# RL6955_IP_SVD register map
Vendor: Realtek
Registers are 32-bit, read-write, reset 0x0 unless marked. A register's access mark holds for its fields unless they carry their own. Offsets are from the block's base; [hi:lo] are bit positions; lines under a group give offsets from that group; {n}, {i} and the like mark numbered series; 'fields as' and 'values as' point back to an identical list.

## RXI300_REG
Base 0x41892000
Same registers: RXI300_S_ELR_REG 0x41892100, RXI300_S_DIR_REG 0x41892200, RXI300_NS_GPR_REG 0x41893000, RXI300_NS_ELR_REG 0x41893100, RXI300_NS_DIR_REG 0x41893200, RXI300_NS_TMO_REG 0x41893300, PPC_S 0x51892000, MPC1_S 0x51892400, MPC2_S 0x51892500, MPC3_S 0x51892600
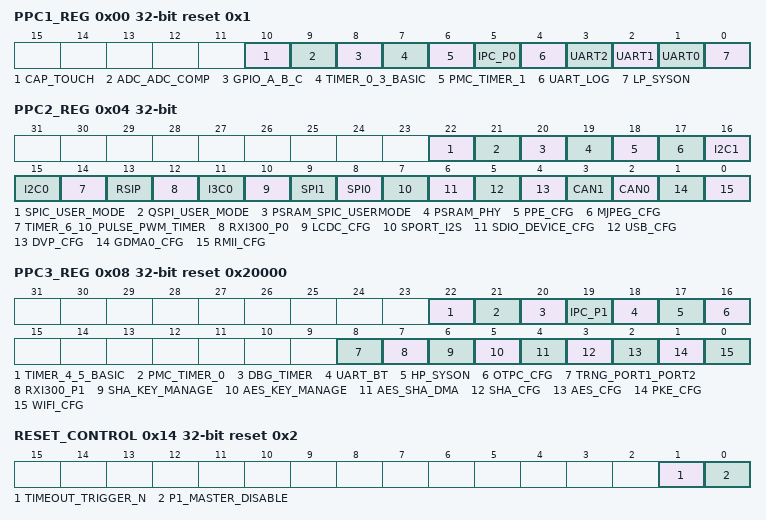
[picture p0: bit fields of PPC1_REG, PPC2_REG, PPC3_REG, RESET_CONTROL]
0x00 PPC1_REG reset 0x1 — PPC1 configure register
  [10] CAP_TOUCH — 1: Non-secure attribution 0: Secure attribution
  [9] ADC_ADC_COMP — 1: Non-secure attribution 0: Secure attribution
  [8] GPIO_A_B_C — 1: Non-secure attribution 0: Secure attribution
  [7] TIMER_0_3_BASIC — 1: Non-secure attribution 0: Secure attribution
  [6] PMC_TIMER_1 — 1: Non-secure attribution 0: Secure attribution
  [5] IPC_P0 — 1: Non-secure attribution 0: Secure attribution
  [4] UART_LOG — 1: Non-secure attribution 0: Secure attribution
  [3] UART2 — 1: Non-secure attribution 0: Secure attribution
  [2] UART1 — 1: Non-secure attribution 0: Secure attribution
  [1] UART0 — 1: Non-secure attribution 0: Secure attribution
  [0] LP_SYSON — 1: Non-secure attribution 0: Secure attribution
0x04 PPC2_REG — PPC2 configure register
  [22] SPIC_USER_MODE — 1: Non-secure attribution 0: Secure attribution
  [21] QSPI_USER_MODE — 1: Non-secure attribution 0: Secure attribution
  [20] PSRAM_SPIC_USERMODE — 1: Non-secure attribution 0: Secure attribution
  [19] PSRAM_PHY — 1: Non-secure attribution 0: Secure attribution
  [18] PPE_CFG — 1: Non-secure attribution 0: Secure attribution
  [17] MJPEG_CFG — 1: Non-secure attribution 0: Secure attribution
  [16] I2C1 — 1: Non-secure attribution 0: Secure attribution
  [15] I2C0 — 1: Non-secure attribution 0: Secure attribution
  [14] TIMER_6_10_PULSE_PWM_TIMER — 1: Non-secure attribution 0: Secure attribution
  [13] RSIP — 1: Non-secure attribution 0: Secure attribution
  [12] RXI300_P0 — 1: Non-secure attribution 0: Secure attribution
  [11] I3C0 — 1: Non-secure attribution 0: Secure attribution
  [10] LCDC_CFG — 1: Non-secure attribution 0: Secure attribution
  [9] SPI1 — 1: Non-secure attribution 0: Secure attribution
  [8] SPI0 — 1: Non-secure attribution 0: Secure attribution
  [7] SPORT_I2S — 1: Non-secure attribution 0: Secure attribution
  [6] SDIO_DEVICE_CFG — 1: Non-secure attribution 0: Secure attribution
  [5] USB_CFG — 1: Non-secure attribution 0: Secure attribution
  [4] DVP_CFG — 1: Non-secure attribution 0: Secure attribution
  [3] CAN1 — 1: Non-secure attribution 0: Secure attribution
  [2] CAN0 — 1: Non-secure attribution 0: Secure attribution
  [1] GDMA0_CFG — 1: Non-secure attribution 0: Secure attribution
  [0] RMII_CFG — 1: Non-secure attribution 0: Secure attribution
0x08 PPC3_REG reset 0x20000 — PPC3 configure register
  [22] TIMER_4_5_BASIC — 1: Non-secure attribution 2: Secure attribution
  [21] PMC_TIMER_0 — 1: Non-secure attribution 1: Secure attribution
  [20] DBG_TIMER — 1: Non-secure attribution 0: Secure attribution
  [19] IPC_P1 — 1: Non-secure attribution 0: Secure attribution
  [18] UART_BT — 1: Non-secure attribution 0: Secure attribution
  [17] HP_SYSON — 1: Non-secure attribution 0: Secure attribution
  [16] OTPC_CFG — 1: Non-secure attribution 0: Secure attribution
  [8] TRNG_PORT1_PORT2 — 1: Non-secure attribution 0: Secure attribution
  [7] RXI300_P1 — 1: Non-secure attribution 0: Secure attribution
  [6] SHA_KEY_MANAGE — 1: Non-secure attribution 0: Secure attribution
  [5] AES_KEY_MANAGE — 1: Non-secure attribution 0: Secure attribution
  [4] AES_SHA_DMA — 1: Non-secure attribution 0: Secure attribution
  [3] SHA_CFG — 1: Non-secure attribution 0: Secure attribution
  [2] AES_CFG — 1: Non-secure attribution 0: Secure attribution
  [1] PKE_CFG — 1: Non-secure attribution 0: Secure attribution
  [0] WIFI_CFG — 1: Non-secure attribution 0: Secure attribution
0x0C PPC_LOCK
  [0] LOCK — PPC lock register. When writing 1'b1 to this bit, PPC will be locked. Note: It can not be written to 1'b0 again until system reset to prevent modification. When PPC is locked, you can not program PPC registers unless system reset.
0x10 DISCONNECT_PLFM1 — Disconnect platform register1
  [0] DISCONNECT_PLFM1 — Platform1-to-platform0 peripheral path are 0x0: connect 0x1: disconnect When writing 1'b1 to this bit, the register willl be locked. NOTE: It can not be written to 1'b0 again until system reset to prevent modification.When this regitster is locked, you can not program this register unless system reset.
0x14 RESET_CONTROL reset 0x2 — Reset flow control register
  [1] TIMEOUT_TRIGGER_N — Trigger all timeout monitors in platform0 to block transaction from platform1. 0x0: trigger timeout 0x1: idle NOTE: The register is not a write-1-clear register. User should set this register to 0x1(idle) after timeout is triggered.
  [0] P1_MASTER_DISABLE — Master enable signal. All master agent of platform1-to-platform are 0x0: enable 0x1: disable
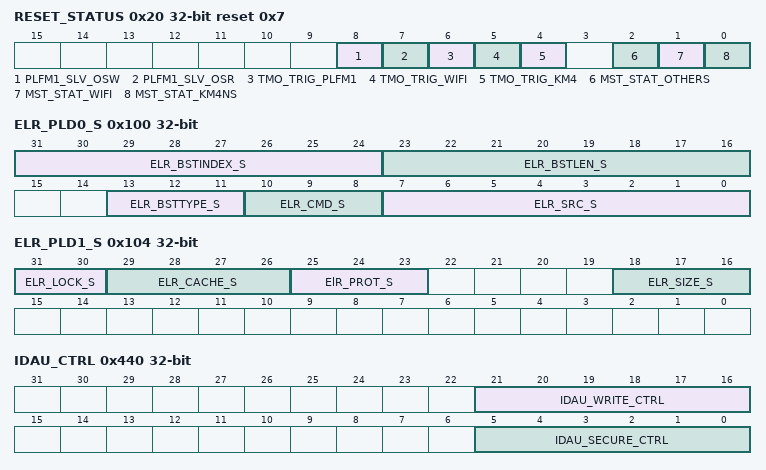
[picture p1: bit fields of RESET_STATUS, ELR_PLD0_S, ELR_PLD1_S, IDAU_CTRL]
0x20 RESET_STATUS ro reset 0x7 — Reset flow status register
  [8] PLFM1_SLV_OSW — Write transaction number of KM4TZ which remains in platform1 slaves.The platform1 slaves are 0x0: idle 0x1: has at least one write OST
  [7] PLFM1_SLV_OSR — Read transaction number of KM4TZ which remains in platform1 slaves.The platform1 slaves are 0x0: idle 0x1: has at least one read OST
  [6] TMO_TRIG_PLFM1 — Status of AES_SHA/SIC/OTPC/WIFI timeout monitor.The timeout is 0x0: disable 0x1: enable
  [5] TMO_TRIG_WIFI — Status of WIFI timeout monitor.The timeout is 0x0: disable 0x0: enable
  [4] TMO_TRIG_KM4 — Status of CPU domain timeout monitor.The timeout is 0x0: disable 0x1: enable
  [2] MST_STAT_OTHERS — Status of AES_SHA/SIC/OTPC/WIFI master agent. The master is 0x0: idle 0x1: active
  [1] MST_STAT_WIFI — Status of WIFI master agent. The master is 0x0: idle 0x1: active
  [0] MST_STAT_KM4NS — Status of KM4NS master agent. The master is 0x0: idle 0x1: active
0x100 ELR_PLD0_S ro — Error log payload register0
  [31:24] ELR_BSTINDEX_S — Burst index of the error request.
  [23:16] ELR_BSTLEN_S — Burst Length of the error request.
  [13:11] ELR_BSTTYPE_S — BurstSeq of the error request.
  [10:8] ELR_CMD_S — CMD of the error request. 0x1: Write command 0x2: Read command
  [7:0] ELR_SRC_S — Error source of the error request. 0x10: secure default slave of P0S0 0x11: secure default slave of P0S1-12~P0S1-16 0x12: secure default slave of P0S1-5~P0S1-7 0x13: secure default slave of P0S1-1~P0S1-4, P0S1-8~P0S1-11 0x14: secure default slave of P0S1-0 0x15: secure default slave of P0S1-22 0x16: secure default slave of P0S1-19~P0S1-21, P0S2 0x17: secure default slave of P0S1-17, P0S1-18 0x20: secure default slave of P2S0 0x21: secure default slave of P3S0 0x22: secure default slave of P4S0
0x104 ELR_PLD1_S ro — Error log payload register1
  [31:30] ELR_LOCK_S — AxLock of the error request.
  [29:26] ELR_CACHE_S — AxCache of the error request.
  [25:23] ElR_PROT_S — AxProt of the error request.
  [18:16] ELR_SIZE_S — Size of the error request.
0x108 ELR_ID_S ro — Error log ID information register
  [31:0] ELR_ID_S — Tagid of the error request. 8'b00000???: M0 access error 8'b000100??: M1 access error 8'b0100????: M2 access error 8'b000101??: M3 access error 8'b0101000?: M4 access error 8'b0001100?: M5 access error 8'b01100???: M6 access error 8'b001?????: M7 access error 8'b1101????: M8 access error 8'b11100???: M9 access error 8'b1111000?: M10 access error 8'b101?????: M11 access error
0x10C ELR_ADR0_S ro — Error log addrress register0
  [31:0] ELR_ADR0_S — Address[31:0] of the error request.
0x110 ELR_ADR1_S ro — Error log addrress register1
  [63:32] ELR_ADR1_S — Address[63:32] of the error request.
0x130 ELR_CODE_S ro — Error code register
  [7:0] ELR_CODE_S — The error code of error request, if it's 0, indicates that there is no error request. 8'h00: No error 8'h02: Secure fault error
0x13C ELR_INTR_CLR_S wo — Error log clear register
  [0] ELR_INTR_CLR_S — Error log interrupt clear. Writing 1'b1 to the register will trigger a 1-cycle pulse interrupt clear. It has to write 1'b1 to this register every time when the error exception occurs. Note that this register is write-only, the return value of reading this register is meaningless.
0x200 NAME ro reset 0x52300 — RXI300 design name register
  [31:0] NAME — The design name of RXI-300.
0x204 VER ro reset 0x300 — RXI300 design version register
  [31:0] VER — The design version of RXI-300.
0x208 RVE ro reset 0x3 — RXI300 design reversion register
  [31:0] REV — The design reversion of RXI-300.
0x20C INST ro — RXI300 design instance number register
  [31:0] INST — The design instance number of RXI-300.
0x210 IMPL_Y ro reset 0x2025 — RXI300 implementation year register
  [31:0] IMPL_Y — The implementatin year of RXI-300. Reset value depends on implementation date.
0x214 IMPL_D ro reset 0x3211627 — RXI300 implementation date register
  [31:0] IMPL_D — The implementatin date of RXI-300. Reset value depends on implementation date.
0x218 DEV ro reset 0x5207433 — RXI300 developer register
  [31:0] DEV — The developer of RXI-300.
0x21C PRO_NUM ro reset 0x6955 — RXI300 project number register
  [31:0] PRO_NUM — The project number of RXI-300.
{0x400+8i} IDAU_BA{i} (i=0..5) — Base address register {i} in IDAU
  [27:12] IDAU_BA{i} — It's the base address of region {i} which can be set as non-secure. [27:12]: base address of region {i}
{0x404+8i} IDAU_LA{i} (i=0..5) — Top address register {i} in IDAU
  [27:12] IDAU_LA{i} — It's the top address of region {i} which can be set as non-secure. [27:12]: top address of region {i}
0x440 IDAU_CTRL — Enable control register in IDAU
  [21:16] IDAU_WRITE_CTRL — Region entry enable After setting WRITE_CTRL bits as 1, corresponding regions is set as write-forbidden.Note that if WRITE_CTRL bits are not enabled, the region remains secure even if ba*i/la*i is set. [16]: enable entry for ba0/la0 0: disable 1: enable [17]: enable entry for ba1/la1 0: disable 1: enable [18]: enable entry for ba2/la2 0: disable 1: enable [19]: enable entry for ba3/la3 0: disable 1: enable [20]: enable entry for ba4/la4 0: disable 1: enable [21]: enable entry for ba5/la5 0: disable 1: enable
  [5:0] IDAU_SECURE_CTRL — Region entry enable After setting SECURE_CTRL bits as 1, corresponding regions is set as non-secure.Note that if SECURE_CTRL bits are not enabled, the region remains secure even if ba*i/la*i is set. [0]: enable entry for ba0/la0 0: disable 1: enable [1]: enable entry for ba1/la1 0: disable 1: enable [2]: enable entry for ba2/la2 0: disable 1: enable [3]: enable entry for ba3/la3 0: disable 1: enable [4]: enable entry for ba4/la4 0: disable 1: enable [5]: enable entry for ba5/la5 0: disable 1: enable
0x444 IDAU_LOCK — Lock control register in IDAU
  [0] IDAU_LOCK — Lock write transfer for all registers in IDAU (including lock register itself) until system reset if it is ebabled. [0]: lock bit for all register in IDAU 0: disable lock 1: enable lock
{0x500+8i} IDAU1_BA{i} (i=0..5) — Base address register {i} in IDAU
  [27:12] IDAU1_BA{i} — It's the base address of region {i} which can be set as non-secure. [27:12]: base address of region {i}
{0x504+8i} IDAU1_LA{i} reset 0xF000000 (i=0..5) — Top address register {i} in IDAU
  [27:12] IDAU1_LA{i} — It's the top address of region {i} which can be set as non-secure. [27:12]: top address of region {i}
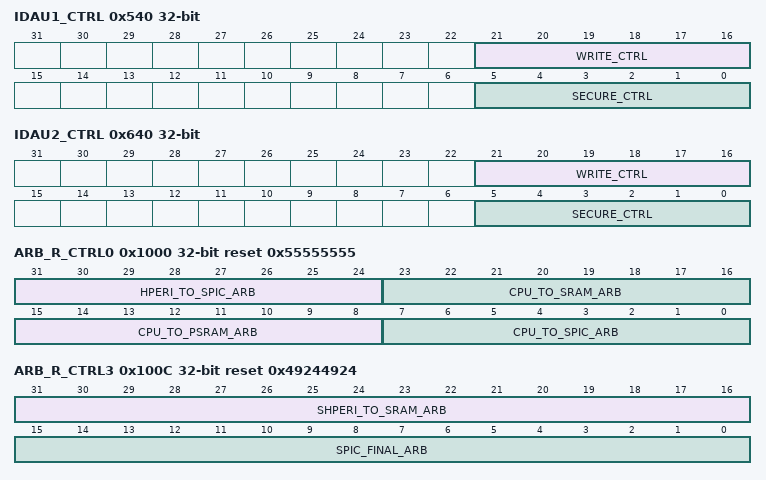
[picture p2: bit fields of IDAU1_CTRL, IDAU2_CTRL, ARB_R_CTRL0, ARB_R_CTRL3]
0x540 IDAU1_CTRL — Enable control register in IDAU
  [21:16] WRITE_CTRL — Region entry enable After setting WRITE_CTRL bits as 1, corresponding regions is set as write-forbidden.Note that if WRITE_CTRL bits are not enabled, the region remains secure even if ba*i/la*i is set. [16]: enable entry for ba0/la0 0: disable 1: enable [17]: enable entry for ba1/la1 0: disable 1: enable [18]: enable entry for ba2/la2 0: disable 1: enable [19]: enable entry for ba3/la3 0: disable 1: enable [20]: enable entry for ba4/la4 0: disable 1: enable [21]: enable entry for ba5/la5 0: disable 1: enable
  [5:0] SECURE_CTRL — Region entry enable After setting SECURE_CTRL bits as 1, corresponding regions is set as non-secure.Note that if SECURE_CTRL bits are not enabled, the region remains secure even if ba*i/la*i is set. [0]: enable entry for ba0/la0 0: disable 1: enable [1]: enable entry for ba1/la1 0: disable 1: enable [2]: enable entry for ba2/la2 0: disable 1: enable [3]: enable entry for ba3/la3 0: disable 1: enable [4]: enable entry for ba4/la4 0: disable 1: enable [5]: enable entry for ba5/la5 0: disable 1: enable
0x544 IDAU1_LOCK — Lock control register in IDAU
  fields as IDAU_LOCK
{0x600+8i} IDAU2_BA{i} (i=0..5) — Base address register {i} in IDAU
  [27:12] IDAU2_BA{i} — It's the base address of region {i} which can be set as non-secure. [27:12]: base address of region {i}
{0x604+8i} IDAU2_LA{i} reset 0xF000000 (i=0..5) — Top address register {i} in IDAU
  [27:12] IDAU2_LA{i} — It's the top address of region {i} which can be set as non-secure. [27:12]: top address of region {i}
0x640 IDAU2_CTRL — Enable control register in IDAU
  fields as IDAU1_CTRL
0x644 IDAU2_LOCK — Lock control register in IDAU
  [0] IDAU_LOCK — Lock write transfer for all registers in IDAU (including lock register itself) until system reset if it is ebabled. [0]: lock bit for all register in IDAU 0: disable lock 1: enable lock [31:1] reserved
0x1000 ARB_R_CTRL0 reset 0x55555555 — The read arbitration control0
  [31:24] HPERI_TO_SPIC_ARB — Read arbitration control register. Each slot should be set by a port number. The port number represents a master group.The master group is shown as following: 0x0: WIFI/AES_SHA/OTPC/SIC 0x1: GDMA And the following shows bit field of each slots: [0]: slot 0 of arbiter [1]: slot 1 of arbiter [2]: slot 2 of arbiter [3]: slot 3 of arbiter [4]: slot 4 of arbiter [5]: slot 5 of arbiter [6]: slot 6 of arbiter [7]: slot 7 of arbiter
  [23:16] CPU_TO_SRAM_ARB — Read arbitration control register. Each slot should be set by a port number. The port number represents a master group.The master group is shown as following: 0x0: KM4TZ 0x1: KM4NS And the following shows bit field of each slots: [0]: slot 0 of arbiter [1]: slot 1 of arbiter [2]: slot 2 of arbiter [3]: slot 3 of arbiter [4]: slot 4 of arbiter [5]: slot 5 of arbiter [6]: slot 6 of arbiter [7]: slot 7 of arbiter
  [15:8] CPU_TO_PSRAM_ARB — Read arbitration control register. Each slot should be set by a port number. The port number represents a master group.The master group is shown as following: 0x0: KM4TZ 0x1: KM4NS And the following shows bit field of each slots: [0]: slot 0 of arbiter [1]: slot 1 of arbiter [2]: slot 2 of arbiter [3]: slot 3 of arbiter [4]: slot 4 of arbiter [5]: slot 5 of arbiter [6]: slot 6 of arbiter [7]: slot 7 of arbiter
  [7:0] CPU_TO_SPIC_ARB — Read arbitration control register. Each slot should be set by a port number. The port number represents a master group.The master group is shown as following: 0x0: KM4TZ 0x1: KM4NS And the following shows bit field of each slots: [0]: slot 0 of arbiter [1]: slot 1 of arbiter [2]: slot 2 of arbiter [3]: slot 3 of arbiter [4]: slot 4 of arbiter [5]: slot 5 of arbiter [6]: slot 6 of arbiter [7]: slot 7 of arbiter
0x1004 ARB_R_CTRL1 reset 0x23444688 — The read arbitration control1
  [29:0] HPERI_TO_PSRAM_ARB — Read arbitration control register. Each slot should be set by a port number. The port number represents a master group.The master group is shown as following: 0x0: WIFI/AES_SHA/OTPC/SIC 0x1: USB 0x2: DVP 0x3: RMII 0x4: GDMA And the following shows bit field of each slots: [2:0]: slot 0 of arbiter [5:3]: slot 1 of arbiter [8:6]: slot 2 of arbiter [11:9]: slot 3 of arbiter [14:12]: slot 4 of arbiter [17:15]: slot 5 of arbiter [20:18]: slot 6 of arbiter [23:21]: slot 7 of arbiter [26:24]: slot 8 of arbiter [29:27]: slot 9 of arbiter
0x1008 ARB_R_CTRL2 reset 0x23444688 — The read arbitration control2
  [29:0] HPERI_TO_SRAM_ARB — Read arbitration control register. Each slot should be set by a port number. The port number represents a master group.The master group is shown as following: 0x0: WIFI/AES_SHA/OTPC/SIC 0x1: USB 0x2: DVP 0x3: RMII 0x4: GDMA And the following shows bit field of each slots: [2:0]: slot 0 of arbiter [5:3]: slot 1 of arbiter [8:6]: slot 2 of arbiter [11:9]: slot 3 of arbiter [14:12]: slot 4 of arbiter [17:15]: slot 5 of arbiter [20:18]: slot 6 of arbiter [23:21]: slot 7 of arbiter [26:24]: slot 8 of arbiter [29:27]: slot 9 of arbiter
0x100C ARB_R_CTRL3 reset 0x49244924 — The read arbitration control3
  [31:16] SHPERI_TO_SRAM_ARB — Read arbitration control register. Each slot should be set by a port number. The port number represents a master group.The master group is shown as following: 0x0: MJPEG 0x1: LCDC 0x2: PPE And the following shows bit field of each slots: [1:0]: slot 0 of arbiter [3:2]: slot 1 of arbiter [5:4]: slot 2 of arbiter [7:6]: slot 3 of arbiter [9:8]: slot 4 of arbiter [11:10]: slot 5 of arbiter [13:12]: slot 6 of arbiter [15:14]: slot 7 of arbiter
  [15:0] SPIC_FINAL_ARB — Read arbitration control register. Each slot should be set by a port number. The port number represents a master group.The master group is shown as following: 0x0: CPU_TO_SPIC_ARB group 0x1: HPERI_TO_SPIC_ARB group 0x2: SHPERI_TO_SPIC_ARB group And the following shows bit field of each slots: [1:0]: slot 0 of arbiter [3:2]: slot 1 of arbiter [5:4]: slot 2 of arbiter [7:6]: slot 3 of arbiter [9:8]: slot 4 of arbiter [11:10]: slot 5 of arbiter [13:12]: slot 6 of arbiter [15:14]: slot 7 of arbiter
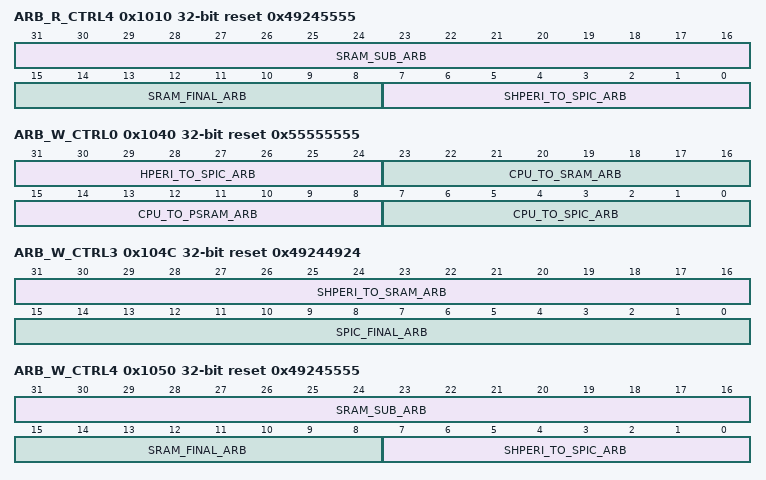
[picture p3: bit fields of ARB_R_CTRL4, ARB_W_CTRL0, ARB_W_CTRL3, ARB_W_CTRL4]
0x1010 ARB_R_CTRL4 reset 0x49245555 — The read arbitration control4
  [31:16] SRAM_SUB_ARB — Read arbitration control register. Each slot should be set by a port number. The port number represents a master group.The master group is shown as following: 0x0: CPU_TO_SRAM_ARB group 0x1: HPERI_TO_SRAM_ARB group 0x2: SHPERI_TO_SRAM_ARB group And the following shows bit field of each slots: [1:0]: slot 0 of arbiter [3:2]: slot 1 of arbiter [5:4]: slot 2 of arbiter [7:6]: slot 3 of arbiter [9:8]: slot 4 of arbiter [11:10]: slot 5 of arbiter [13:12]: slot 6 of arbiter [15:14]: slot 7 of arbiter
  [15:8] SRAM_FINAL_ARB — Read arbitration control register. Each slot should be set by a port number. The port number represents a master group.The master group is shown as following: 0x0: WIFI 0x1: SRAM_SUB_ARB group And the following shows bit field of each slots: [0]: slot 0 of arbiter [1]: slot 1 of arbiter [2]: slot 2 of arbiter [3]: slot 3 of arbiter [4]: slot 4 of arbiter [5]: slot 5 of arbiter [6]: slot 6 of arbiter [7]: slot 7 of arbiter
  [7:0] SHPERI_TO_SPIC_ARB — Read arbitration control register. Each slot should be set by a port number. The port number represents a master group.The master group is shown as following: 0x0: MJPEG 0x1: PPE And the following shows bit field of each slots: [0]: slot 0 of arbiter [1]: slot 1 of arbiter [2]: slot 2 of arbiter [3]: slot 3 of arbiter [4]: slot 4 of arbiter [5]: slot 5 of arbiter [6]: slot 6 of arbiter [7]: slot 7 of arbiter
0x1014 ARB_R_CTRL5 reset 0x23444688 — The read arbitration control5
  [29:0] PSRAM_FINAL_ARB — Read arbitration control register. Each slot should be set by a port number. The port number represents a master group.The master group is shown as following: 0x0: CPU_TO_PSRAM_ARB group 0x1: HPERI_TO_PSRAM_ARB group 0x2: MJPEG 0x3: LCDC 0x4: PPE And the following shows bit field of each slots: [2:0]: slot 0 of arbiter [5:3]: slot 1 of arbiter [8:6]: slot 2 of arbiter [11:9]: slot 3 of arbiter [14:12]: slot 4 of arbiter [17:15]: slot 5 of arbiter [20:18]: slot 6 of arbiter [23:21]: slot 7 of arbiter [26:24]: slot 8 of arbiter [29:27]: slot 9 of arbiter
0x1040 ARB_W_CTRL0 reset 0x55555555 — The write arbitration control0
  [31:24] HPERI_TO_SPIC_ARB — Write arbitration control register. Each slot should be set by a port number. The port number represents a master group.The master group is shown as following: 0x0: WIFI/AES_SHA/OTPC/SIC 0x1:GDMA And the following shows bit field of each slots: [0]: slot 0 of arbiter [1]: slot 1 of arbiter [2]: slot 2 of arbiter [3]: slot 3 of arbiter [4]: slot 4 of arbiter [5]: slot 5 of arbiter [6]: slot 6 of arbiter [7]: slot 7 of arbiter
  [23:16] CPU_TO_SRAM_ARB — Write arbitration control register. Each slot should be set by a port number. The port number represents a master group.The master group is shown as following: 0x0: KM4TZ 0x1: KM4NS And the following shows bit field of each slots: [0]: slot 0 of arbiter [1]: slot 1 of arbiter [2]: slot 2 of arbiter [3]: slot 3 of arbiter [4]: slot 4 of arbiter [5]: slot 5 of arbiter [6]: slot 6 of arbiter [7]: slot 7 of arbiter
  [15:8] CPU_TO_PSRAM_ARB — Write arbitration control register. Each slot should be set by a port number. The port number represents a master group.The master group is shown as following: 0x0: KM4TZ 0x1: KM4NS And the following shows bit field of each slots: [0]: slot 0 of arbiter [1]: slot 1 of arbiter [2]: slot 2 of arbiter [3]: slot 3 of arbiter [4]: slot 4 of arbiter [5]: slot 5 of arbiter [6]: slot 6 of arbiter [7]: slot 7 of arbiter
  [7:0] CPU_TO_SPIC_ARB — Write arbitration control register. Each slot should be set by a port number. The port number represents a master group.The master group is shown as following: 0x0: KM4TZ 0x1: KM4NS And the following shows bit field of each slots: [0]: slot 0 of arbiter [1]: slot 1 of arbiter [2]: slot 2 of arbiter [3]: slot 3 of arbiter [4]: slot 4 of arbiter [5]: slot 5 of arbiter [6]: slot 6 of arbiter [7]: slot 7 of arbiter
0x1044 ARB_W_CTRL1 reset 0x23444688 — The write arbitration control1
  [29:0] HPERI_TO_PSRAM_ARB — Write arbitration control register. Each slot should be set by a port number. The port number represents a master group.The master group is shown as following: 0x0: WIFI/AES_SHA/OTPC/SIC 0x1: USB 0x2: DVP 0x3: RMII 0x4: GDMA And the following shows bit field of each slots: [2:0]: slot 0 of arbiter [5:3]: slot 1 of arbiter [8:6]: slot 2 of arbiter [11:9]: slot 3 of arbiter [14:12]: slot 4 of arbiter [17:15]: slot 5 of arbiter [20:18]: slot 6 of arbiter [23:21]: slot 7 of arbiter [26:24]: slot 8 of arbiter [29:27]: slot 9 of arbiter
0x1048 ARB_W_CTRL2 reset 0x23444688 — The write arbitration control2
  [29:0] HPERI_TO_SRAM_ARB — Write arbitration control register. Each slot should be set by a port number. The port number represents a master group.The master group is shown as following: 0x0: WIFI/AES_SHA/OTPC/SIC 0x1: USB 0x2: DVP 0x3: RMII 0x4: GDMA And the following shows bit field of each slots: [2:0]: slot 0 of arbiter [5:3]: slot 1 of arbiter [8:6]: slot 2 of arbiter [11:9]: slot 3 of arbiter [14:12]: slot 4 of arbiter [17:15]: slot 5 of arbiter [20:18]: slot 6 of arbiter [23:21]: slot 7 of arbiter [26:24]: slot 8 of arbiter [29:27]: slot 9 of arbiter
0x104C ARB_W_CTRL3 reset 0x49244924 — The write arbitration control3
  [31:16] SHPERI_TO_SRAM_ARB — Write arbitration control register. Each slot should be set by a port number. The port number represents a master group.The master group is shown as following: 0x0: MJPEG 0x1: LCDC 0x2: PPE And the following shows bit field of each slots: [1:0]: slot 0 of arbiter [3:2]: slot 1 of arbiter [5:4]: slot 2 of arbiter [7:6]: slot 3 of arbiter [9:8]: slot 4 of arbiter [11:10]: slot 5 of arbiter [13:12]: slot 6 of arbiter [15:14]: slot 7 of arbiter
  [15:0] SPIC_FINAL_ARB — Write arbitration control register. Each slot should be set by a port number. The port number represents a master group.The master group is shown as following: 0x0: CPU_TO_SPIC_ARB group 0x1: HPERI_TO_SPIC_ARB group 0x2: SHPERI_TO_SPIC_ARB group And the following shows bit field of each slots: [1:0]: slot 0 of arbiter [3:2]: slot 1 of arbiter [5:4]: slot 2 of arbiter [7:6]: slot 3 of arbiter [9:8]: slot 4 of arbiter [11:10]: slot 5 of arbiter [13:12]: slot 6 of arbiter [15:14]: slot 7 of arbiter
0x1050 ARB_W_CTRL4 reset 0x49245555 — The write arbitration control4
  [31:16] SRAM_SUB_ARB — Write arbitration control register. Each slot should be set by a port number. The port number represents a master group.The master group is shown as following: 0x0: CPU_TO_SRAM_ARB group 0x1: HPERI_TO_SRAM_ARB group 0x2: SHPERI_TO_SRAM_ARB group And the following shows bit field of each slots: [1:0]: slot 0 of arbiter [3:2]: slot 1 of arbiter [5:4]: slot 2 of arbiter [7:6]: slot 3 of arbiter [9:8]: slot 4 of arbiter [11:10]: slot 5 of arbiter [13:12]: slot 6 of arbiter [15:14]: slot 7 of arbiter
  [15:8] SRAM_FINAL_ARB — Write arbitration control register. Each slot should be set by a port number. The port number represents a master group.The master group is shown as following: 0x0: WIFI 0x1: SRAM_SUB_ARB group And the following shows bit field of each slots: [0]: slot 0 of arbiter [1]: slot 1 of arbiter [2]: slot 2 of arbiter [3]: slot 3 of arbiter [4]: slot 4 of arbiter [5]: slot 5 of arbiter [6]: slot 6 of arbiter [7]: slot 7 of arbiter
  [7:0] SHPERI_TO_SPIC_ARB — Write arbitration control register. Each slot should be set by a port number. The port number represents a master group.The master group is shown as following: 0x0: MJPEG 0x1: PPE And the following shows bit field of each slots: [0]: slot 0 of arbiter [1]: slot 1 of arbiter [2]: slot 2 of arbiter [3]: slot 3 of arbiter [4]: slot 4 of arbiter [5]: slot 5 of arbiter [6]: slot 6 of arbiter [7]: slot 7 of arbiter
0x1054 ARB_W_CTRL5 reset 0x23444688 — The write arbitration control5
  [29:0] PSRAM_FINAL_ARB — write arbitration control register. Each slot should be set by a port number. The port number represents a master group.The master group is shown as following: 0x0: CPU_TO_PSRAM_ARB group 0x1: HPERI_TO_PSRAM_ARB group 0x2: MJPEG 0x3: LCDC 0x4: PPE And the following shows bit field of each slots: [2:0]: slot 0 of arbiter [5:3]: slot 1 of arbiter [8:6]: slot 2 of arbiter [11:9]: slot 3 of arbiter [14:12]: slot 4 of arbiter [17:15]: slot 5 of arbiter [20:18]: slot 6 of arbiter [23:21]: slot 7 of arbiter [26:24]: slot 8 of arbiter [29:27]: slot 9 of arbiter
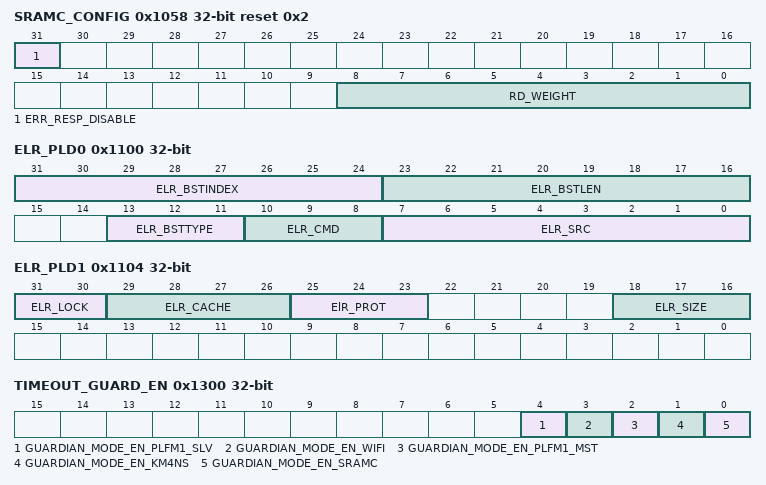
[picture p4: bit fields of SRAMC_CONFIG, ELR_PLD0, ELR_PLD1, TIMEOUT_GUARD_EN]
0x1058 SRAMC_CONFIG reset 0x2
  [31] ERR_RESP_DISABLE — 0x0: enable error response of SRAMC 0x1: disable error response of SRAMC
  [8:0] RD_WEIGHT — RD weight of SRAMC
0x1100 ELR_PLD0 ro — Error log payload register0
  [31:24] ELR_BSTINDEX — Burst index of the error request.
  [23:16] ELR_BSTLEN — Burst Length of the error request.
  [13:11] ELR_BSTTYPE — BurstSeq of the error request.
  [10:8] ELR_CMD — CMD of the error request. 0x1: Write command 0x2: Read command
  [7:0] ELR_SRC — Error source of the error request. 0x00: Address hole default slave of M0,M8 group 0x01: Address hole default slave of M1, M3, M5, M7, M9-M11 group 0x02: Address hole default slave of M2, M4, M6 0x03: Address hole default slave of P3S0 group 0x40: master timeout of KM4NS 0x41: master timeout of PLFM1_MST(M9-M11) 0x42: master timeout of WIFI 0x43: slave timeout of KM4TZ to PLFM1 0x50: slave timeout of SRAMC
0x1104 ELR_PLD1 ro — Error log payload register1
  [31:30] ELR_LOCK — AxLock of the error request.
  [29:26] ELR_CACHE — AxCache of the error request.
  [25:23] ElR_PROT — AxProt of the error request.
  [18:16] ELR_SIZE — Size of the error request.
0x1108 ELR_ID ro — Error log ID information register
  [31:0] ELR_ID — Tagid of the error request. 8'b00000???: M0 access error 8'b000100??: M1 access error 8'b0100????: M2 access error 8'b000101??: M3 access error 8'b0101000?: M4 access error 8'b0001100?: M5 access error 8'b01100???: M6 access error 8'b001?????: M7 access error 8'b1101????: M8 access error 8'b11100???: M9 access error 8'b1111000?: M10 access error 8'b101?????: M11 access error
0x110C ELR_ADR0 ro — Error log addrress register0
  [31:0] ELR_ADR0 — Address[31:0] of the error request.
0x1110 ELR_ADR1 ro — Error log addrress register1
  [63:32] ELR_ADR1 — Address[63:32] of the error request.
0x1130 ELR_CODE ro — Error code register
  [7:0] ELR_CODE — The error code of error request, if it's 0, indicates that there is no error request. 8'h00: No error 8'h01: Address hole error 8'h2C: AXI master agent wdata timeout 8'h2D: AXI master agent write response timeout 8'h2E: AXI master agent write response timeout 8'h30: AXI SRAM controller grant timeout 8'h38: AXI slave agent arready timeout 8'h39: AXI slave agent rvalid timeout 8'h3A: AXI slave agent arready timeout 8'h3B: AXI slave agent wready timeout 8'h3C: AXI slave agent bvalid timeout
0x113C ELR_INTR_CLR wo — Error log clear register
  [0] ELR_INTR_CLR — Error log interrupt clear. Writing 1'b1 to the register will trigger a 1-cycle pulse interrupt clear. It has to write 1'b1 to this register every time when the error exception occurs. Note that this register is write-only, the return value of reading this register is meaningless.
0x1300 TIMEOUT_GUARD_EN — Timeout guardian enable register
  [4] GUARDIAN_MODE_EN_PLFM1_SLV — The enable of platform1 slave timeout monitor 0x0: Disable timeout check 0x1: Enable timeoute check
  [3] GUARDIAN_MODE_EN_WIFI — The enable of WIFI timeout monitor 0x0: Disable timeout check 0x1: Enable timeoute check
  [2] GUARDIAN_MODE_EN_PLFM1_MST — The enable of SIC/OTPC/ARS_SHA/GDMA timeout monitor 0x0: Disable timeout check 0x1: Enable timeoute check
  [1] GUARDIAN_MODE_EN_KM4NS — The enable of KM4NS timeout monitor 0x0: Disable timeout check 0x0: Enable timeoute check
  [0] GUARDIAN_MODE_EN_SRAMC — The enable of SRAMC timeout monitor 0x0: Disable timeout check 0x1: Enable timeoute check
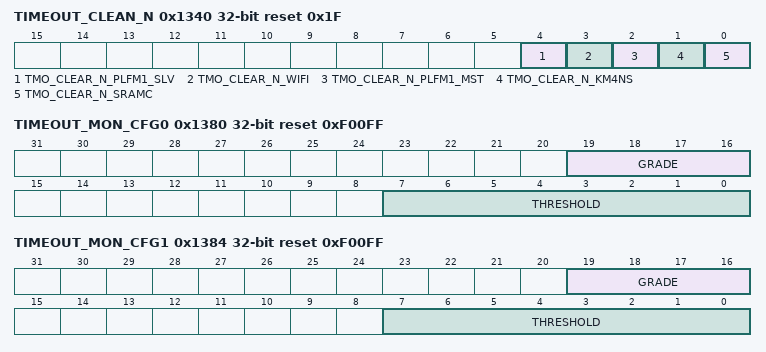
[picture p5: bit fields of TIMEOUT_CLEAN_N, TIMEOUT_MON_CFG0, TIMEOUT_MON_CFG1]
0x1340 TIMEOUT_CLEAN_N reset 0x1F — Timeout clear register
  [4] TMO_CLEAR_N_PLFM1_SLV — The register can only written to 0 when a platform1 time out occures, and automatically clear this register by hardware
  [3] TMO_CLEAR_N_WIFI — The register can only written to 0 when a WIFI time out occures, and automatically clear this register by hardware
  [2] TMO_CLEAR_N_PLFM1_MST — The register can only written to 0 when a SIC/OTPC/ARS_SHA/GDMA time out occures, and automatically clear this register by hardware
  [1] TMO_CLEAR_N_KM4NS — The register can only written to 0 when a KM4NS time out occures, and automatically clear this register by hardware
  [0] TMO_CLEAR_N_SRAMC — The register can only written to 0 when a SRAMC time out occures, and automatically clear this register by hardware
0x1380 TIMEOUT_MON_CFG0 reset 0xF00FF — Timeout monitor configuration register0
  [19:16] GRADE — Timeout grade Timeout total cycle = [256*(2^(grade-1) +1)*threshold] - inaccurate Note1: the range of inaccurate = 0 ~ [256*(2^(grade-1) +1)-2] Note2: If threshold is 0x0, the Timeout_total_cycle is always 1
  [7:0] THRESHOLD — Timeout threshold
0x1384 TIMEOUT_MON_CFG1 reset 0xF00FF — Timeout monitor configuration register0
  fields as TIMEOUT_MON_CFG0
